VERSION "Honda Accord B-CAN transmitter grouping"

NS_ :

BS_:

BU_: METER MICU XXX UNKNOWN

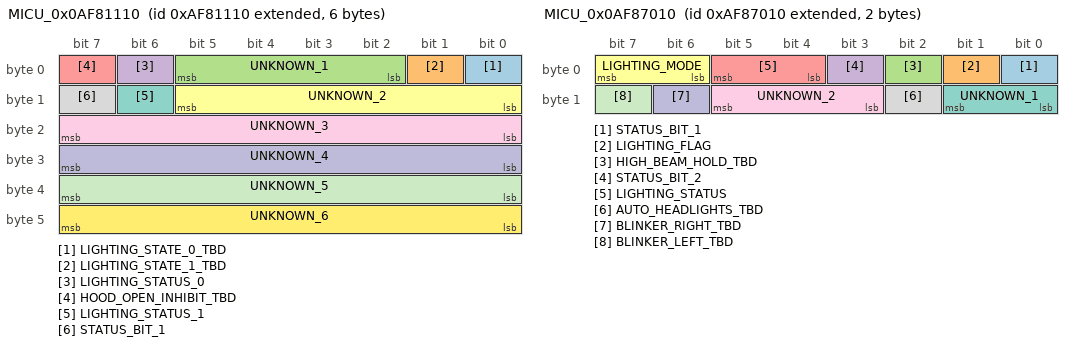
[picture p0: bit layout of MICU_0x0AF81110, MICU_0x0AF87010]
BO_ 2331513104 MICU_0x0AF81110: 6 MICU
 SG_ LIGHTING_STATE_0_TBD : 0|1@1+ (1,0) [0|1] ""  UNKNOWN
 SG_ LIGHTING_STATE_1_TBD : 1|1@1+ (1,0) [0|1] ""  UNKNOWN
 SG_ UNKNOWN_1 : 2|4@1+ (1,0) [0|15] ""  UNKNOWN
 SG_ LIGHTING_STATUS_0 : 6|1@1+ (1,0) [0|1] ""  UNKNOWN
 SG_ HOOD_OPEN_INHIBIT_TBD : 7|1@1+ (1,0) [0|1] ""  UNKNOWN
 SG_ UNKNOWN_2 : 8|6@1+ (1,0) [0|63] ""  UNKNOWN
 SG_ LIGHTING_STATUS_1 : 14|1@1+ (1,0) [0|1] ""  UNKNOWN
 SG_ STATUS_BIT_1 : 15|1@1+ (1,0) [0|1] ""  UNKNOWN
 SG_ UNKNOWN_3 : 16|8@1+ (1,0) [0|255] ""  UNKNOWN
 SG_ UNKNOWN_4 : 24|8@1+ (1,0) [0|255] ""  UNKNOWN
 SG_ UNKNOWN_5 : 32|8@1+ (1,0) [0|255] ""  UNKNOWN
 SG_ UNKNOWN_6 : 40|8@1+ (1,0) [0|255] ""  UNKNOWN

BO_ 2331537424 MICU_0x0AF87010: 2 MICU
 SG_ STATUS_BIT_1 : 0|1@1+ (1,0) [0|1] ""  UNKNOWN
 SG_ LIGHTING_FLAG : 1|1@1+ (1,0) [0|1] ""  UNKNOWN
 SG_ HIGH_BEAM_HOLD_TBD : 2|1@1+ (1,0) [0|1] ""  UNKNOWN
 SG_ STATUS_BIT_2 : 3|1@1+ (1,0) [0|1] ""  UNKNOWN
 SG_ LIGHTING_STATUS : 4|2@1+ (1,0) [0|3] ""  UNKNOWN
 SG_ LIGHTING_MODE : 6|2@1+ (1,0) [0|3] ""  UNKNOWN
 SG_ UNKNOWN_1 : 8|2@1+ (1,0) [0|3] ""  UNKNOWN
 SG_ AUTO_HEADLIGHTS_TBD : 10|1@1+ (1,0) [0|1] ""  UNKNOWN
 SG_ UNKNOWN_2 : 11|3@1+ (1,0) [0|7] ""  UNKNOWN
 SG_ BLINKER_RIGHT_TBD : 14|1@1+ (1,0) [0|1] ""  UNKNOWN
 SG_ BLINKER_LEFT_TBD : 15|1@1+ (1,0) [0|1] ""  UNKNOWN

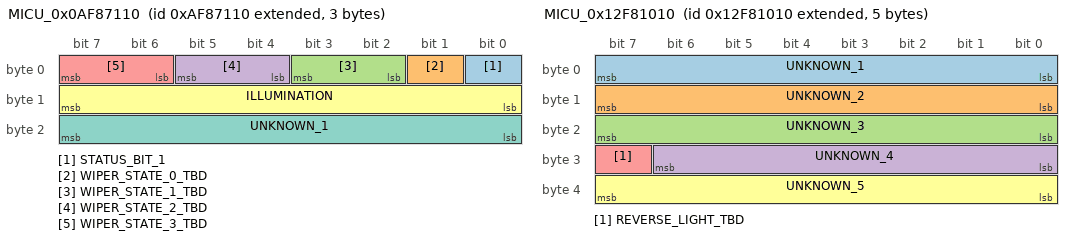
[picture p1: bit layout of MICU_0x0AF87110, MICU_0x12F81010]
BO_ 2331537680 MICU_0x0AF87110: 3 MICU
 SG_ STATUS_BIT_1 : 0|1@1+ (1,0) [0|1] ""  UNKNOWN
 SG_ WIPER_STATE_0_TBD : 1|1@1+ (1,0) [0|1] ""  UNKNOWN
 SG_ WIPER_STATE_1_TBD : 2|2@1+ (1,0) [0|3] ""  UNKNOWN
 SG_ WIPER_STATE_2_TBD : 4|2@1+ (1,0) [0|3] ""  UNKNOWN
 SG_ WIPER_STATE_3_TBD : 6|2@1+ (1,0) [0|3] ""  UNKNOWN
 SG_ ILLUMINATION : 8|8@1+ (1,0) [0|255] ""  UNKNOWN
 SG_ UNKNOWN_1 : 16|8@1+ (1,0) [0|255] ""  UNKNOWN

BO_ 2398622992 MICU_0x0EF81510: 1 MICU
 SG_ UNKNOWN_1 : 0|8@1+ (1,0) [0|255] ""  UNKNOWN

BO_ 2398625808 MICU_0x0EF82010: 1 MICU
 SG_ UNKNOWN_1 : 0|8@1+ (1,0) [0|255] ""  UNKNOWN

BO_ 2465730576 MICU_0x12F81010: 5 MICU
 SG_ UNKNOWN_1 : 0|8@1+ (1,0) [0|255] ""  UNKNOWN
 SG_ UNKNOWN_2 : 8|8@1+ (1,0) [0|255] ""  UNKNOWN
 SG_ UNKNOWN_3 : 16|8@1+ (1,0) [0|255] ""  UNKNOWN
 SG_ UNKNOWN_4 : 24|7@1+ (1,0) [0|127] ""  UNKNOWN
 SG_ REVERSE_LIGHT_TBD : 31|1@1+ (1,0) [0|1] ""  UNKNOWN
 SG_ UNKNOWN_5 : 32|8@1+ (1,0) [0|255] ""  UNKNOWN

BO_ 2465737744 MICU_0x12F82C10: 1 MICU
 SG_ UNKNOWN_1 : 0|8@1+ (1,0) [0|255] ""  UNKNOWN

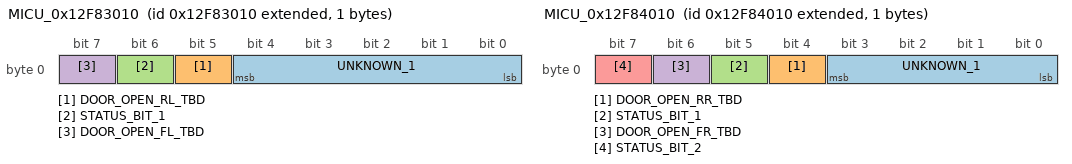
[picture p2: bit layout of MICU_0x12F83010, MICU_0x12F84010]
BO_ 2465738768 MICU_0x12F83010: 1 MICU
 SG_ UNKNOWN_1 : 0|5@1+ (1,0) [0|31] ""  UNKNOWN
 SG_ DOOR_OPEN_RL_TBD : 5|1@1+ (1,0) [0|1] ""  UNKNOWN
 SG_ STATUS_BIT_1 : 6|1@1+ (1,0) [0|1] ""  UNKNOWN
 SG_ DOOR_OPEN_FL_TBD : 7|1@1+ (1,0) [0|1] ""  UNKNOWN

BO_ 2465739024 MICU_0x12F83110: 1 MICU
 SG_ UNKNOWN_1 : 0|8@1+ (1,0) [0|255] ""  UNKNOWN

BO_ 2465739280 MICU_0x12F83210: 1 MICU
 SG_ UNKNOWN_1 : 0|8@1+ (1,0) [0|255] ""  UNKNOWN

BO_ 2465739792 MICU_0x12F83410: 1 MICU
 SG_ UNKNOWN_1 : 0|8@1+ (1,0) [0|255] ""  UNKNOWN

BO_ 2465742864 MICU_0x12F84010: 1 MICU
 SG_ UNKNOWN_1 : 0|4@1+ (1,0) [0|15] ""  UNKNOWN
 SG_ DOOR_OPEN_RR_TBD : 4|1@1+ (1,0) [0|1] ""  UNKNOWN
 SG_ STATUS_BIT_1 : 5|1@1+ (1,0) [0|1] ""  UNKNOWN
 SG_ DOOR_OPEN_FR_TBD : 6|1@1+ (1,0) [0|1] ""  UNKNOWN
 SG_ STATUS_BIT_2 : 7|1@1+ (1,0) [0|1] ""  UNKNOWN

BO_ 2465743120 MICU_0x12F84110: 1 MICU
 SG_ UNKNOWN_1 : 0|8@1+ (1,0) [0|255] ""  UNKNOWN

BO_ 2465743376 MICU_0x12F84210: 1 MICU
 SG_ UNKNOWN_1 : 0|8@1+ (1,0) [0|255] ""  UNKNOWN

BO_ 2465743632 MICU_0x12F84310: 1 MICU
 SG_ UNKNOWN_1 : 0|7@1+ (1,0) [0|127] ""  UNKNOWN
 SG_ TRUNK_OPEN_TBD : 7|1@1+ (1,0) [0|1] ""  UNKNOWN

BO_ 2465757200 MICU_0x12F87810: 1 MICU
 SG_ UNKNOWN_1 : 0|8@1+ (1,0) [0|255] ""  UNKNOWN
